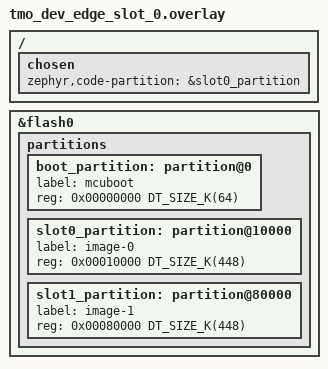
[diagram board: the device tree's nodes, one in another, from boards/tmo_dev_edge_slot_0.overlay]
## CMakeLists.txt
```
# Copyright (c) 2022 T-Mobile USA, Inc.
#
# SPDX-License-Identifier: Apache-2.0

cmake_minimum_required(VERSION 3.20.0)

find_package(Zephyr REQUIRED HINTS $ENV{ZEPHYR_BASE})
project(wake_sleep)

# TODO: Remove the following after the stderror.h workacound is addressed/removed.
#
# add_definitions(-include /Users/john/Work/zephyrproject-rebase/DevEdge-IoTDevKit-ZephyrSDK/samples/wake_sleep/src/stderror.h)
# target_precompile_headers(app
# #   PUBLIC
# #     project_header.h
#   PRIVATE
#     [["src/stderror.h"]]
#     <unordered_map>
# )

# TODO: ...additionally, uncomment the following and remove the subquent two lines
# target_sources(app PRIVATE "src/main.c")
FILE(GLOB app_sources src/*.c)
target_sources(app PRIVATE ${app_sources})
```

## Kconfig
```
# Copyright (c) 2022 T-Mobile USA, Inc.
#
# SPDX-License-Identifier: Apache-2.0

mainmenu "wake_sleep application settings"

config WAKE_TIMER_DURATION
    int "Wake timer timeout in seconds, 0 = diaabled"
    default 0

config WAKE_TIMER_PERIOD
    int "Wake timer period in seconds, 0 = disabled"
    default 0

source "Kconfig.zephyr"
```

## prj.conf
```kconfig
# Copyright (c) 2022 T-Mobile USA, Inc.
#
# SPDX-License-Identifier: Apache-2.0

# UART support
# CONFIG_SERIAL=y
# CONFIG_SHELL_BACKEND_SERIAL_RX_RING_BUFFER_SIZE=1024

# CONFIG_RING_BUFFER=y
# CONFIG_SOC_FLASH_GECKO=y

# CONFIG_ADC=y
# CONFIG_ADC_SHELL=n
# Enable support for the flash hardware.
# CONFIG_FLASH=y
# CONFIG_I2C=y

# CONFIG_SPI=y
# CONFIG_SPI_NOR=y
# CONFIG_SPI_GECKO=y

# Murata 1SC modem support
CONFIG_MODEM=y
# CONFIG_MODEM_SHELL=y
CONFIG_MODEM_MURATA_1SC=y
CONFIG_MODEM_MURATA_1SC_APN="CATM.T-MOBILE.COM"

# Generic networking options
CONFIG_NETWORKING=y
# CONFIG_NET_SHELL=n
CONFIG_NET_NATIVE=n
CONFIG_NET_OFFLOAD=y
CONFIG_NET_IPV6_DAD=n
CONFIG_NET_UDP=n
CONFIG_NET_TCP=n
CONFIG_NET_IPV6=n
CONFIG_NET_IPV4=y
CONFIG_DNS_RESOLVER=n
CONFIG_POSIX_MAX_FDS=15
CONFIG_HTTP_CLIENT=n

# Network management events
# CONFIG_NET_CONNECTION_MANAGER=y
# CONFIG_NET_MGMT=y
# CONFIG_NET_MGMT_EVENT=y

# Debugging
# CONFIG_DEBUG_OPTIMIZATIONS=y

# Logging
CONFIG_LOG=y
CONFIG_LOG_MODE_MINIMAL=y
# CONFIG_LOG_FUNC_NAME_PREFIX_ERR=y
# CONFIG_LOG_FUNC_NAME_PREFIX_WRN=y
# CONFIG_LOG_FUNC_NAME_PREFIX_INF=y
# CONFIG_LOG_FUNC_NAME_PREFIX_DBG=y
# CONFIG_LOG_BACKEND_SHOW_COLOR=y
# CONFIG_LOG_BACKEND_FORMAT_TIMESTAMP=y
# CONFIG_LOG_TIMESTAMP_64BIT=y
# CONFIG_NET_LOG=y

# Required to disable default behavior of deep sleep on timeout
# CONFIG_CONSOLE_SUBSYS=y
# CONFIG_CONSOLE_GETLINE=y

# Network buffers
# CONFIG_NET_PKT_RX_COUNT=1
# CONFIG_NET_PKT_TX_COUNT=1
# CONFIG_NET_BUF_RX_COUNT=1
# CONFIG_NET_BUF_TX_COUNT=1
# CONFIG_NET_CONTEXT_NET_PKT_POOL=y
# CONFIG_NET_BUF_DATA_SIZE=60

# RS9116
CONFIG_WIFI=y
CONFIG_WIFI_RS9116W=y
# CONFIG_GPIO=y

#CONFIG_TEST_RANDOM_GENERATOR=y

# CONFIG_INIT_STACKS=y

# CONFIG_MBEDTLS_DTLS=y

# CONFIG_NET_SOCKETS=y
# CONFIG_NET_SOCKETS_OFFLOAD=y
# CONFIG_NET_SOCKETS_POSIX_NAMES=y
# CONFIG_NET_SOCKETS_POLL_MAX=4
# CONFIG_NET_SOCKETS_SOCKOPT_TLS=y
# CONFIG_NET_SOCKETS_TLS_MAX_CONTEXTS=4
# CONFIG_NET_SOCKETS_ENABLE_DTLS=y


# Bluetooth / BLE
# CONFIG_BT=y
# CONFIG_BT_CUSTOM=y
# CONFIG_BT_RS9116W=y
# CONFIG_BT_PERIPHERAL=y
# CONFIG_BT_SMP=y
# CONFIG_BT_MAX_PAIRED=2
# CONFIG_BT_DEBUG=n

# Sensors
# CONFIG_SENSOR=y
# CONFIG_SENSOR_SHELL=y

# Stack sizes
# CONFIG_MAIN_STACK_SIZE=4096
# CONFIG_SHELL_STACK_SIZE=4096

# MBED TLS configuration
# CONFIG_MBEDTLS=y
# CONFIG_MBEDTLS_BUILTIN=y

# CONFIG_NEWLIB_LIBC=y
# CONFIG_MINIMAL_LIBC_MALLOC=y
# CONFIG_MINIMAL_LIBC_MALLOC_ARENA_SIZE=2048

# Set number IPv4 network interfaces
# CONFIG_NET_IF_MAX_IPV4_COUNT=2
# CONFIG_NET_IF_MAX_IPV6_COUNT=2

#CONFIG_FS_LOG_LEVEL_DBG=y

# CONFIG_HEAP_MEM_POOL_SIZE=16384

# CONFIG_SHELL=y
# CONFIG_SHELL_LOG_LEVEL_INF=y
# CONFIG_SHELL_CMD_BUFF_SIZE=2100

# CONFIG_FILE_SYSTEM=y
# CONFIG_FILE_SYSTEM_SHELL=y
# CONFIG_FILE_SYSTEM_LITTLEFS=y

# CONFIG_FLASH_MAP=y
# CONFIG_FLASH_PAGE_LAYOUT=y

# CONFIG_RS9116W_TLS_OFFLOAD=y

# CONFIG_TMO_SHELL_SSID=""
# CONFIG_TMO_SHELL_PSK=""

# CONFIG_RS9116_DNS_SERVER_IP_ADDRESSES=y
# CONFIG_RS9116_IPV4_DNS_SERVER1="8.8.8.8"
# CONFIG_RS9116_IPV6_DNS_SERVER1="2001:4860:4860::8888"

# CONFIG_MODEM_MURATA_1SC_SOCKET_COUNT=4
# CONFIG_WISECONNECT_SOCKETS_COUNT=6

# CONFIG_SHELL_GETOPT=y
# CONFIG_PING=y

# CONFIG_MODEM_SMS_IN_MSG_MAX_LEN=200
# CONFIG_MODEM_SMS_OUT_MSG_MAX_LEN=200

#Ekermit
# CONFIG_SEGGER_RTT_MODE_BLOCK_IF_FIFO_FULL=y
# CONFIG_LOG_BACKEND_RTT=n
# CONFIG_TMO_SHELL_BUILD_EK=y

#Power Managment
CONFIG_PM=y
CONFIG_PM_DEVICE=y

# CONFIG_BT_DEVICE_NAME_DYNAMIC=y
# CONFIG_LOG_PRINTK=n

# CONFIG_THREAD_NAME=y
# CONFIG_STATS=y
# CONFIG_PM_STATS=y
# CONFIG_IDLE_STACK_SIZE=640
# CONFIG_ZTEST_NEW_API=y

# The following is for the accelorometer
# CONFIG_STDOUT_CONSOLE=y
# CONFIG_I2C=y
# CONFIG_SENSOR=y
# CONFIG_LIS2DW12=y
# CONFIG_LIS2DW12_TRIGGER_GLOBAL_THREAD=y
# CONFIG_LIS2DW12_TAP=y
# CONFIG_LIS2DW12_THRESHOLD=y
# CONFIG_CBPRINTF_FP_SUPPORT=y
# CONFIG_ASSERT=y

# CONFIG_LED_PWM=y
# CONFIG_PWM=y
# # CONFIG_PWM_SHELL=y
# CONFIG_PWM_GECKO=y
CONFIG_GPIO=y

# Stack size
CONFIG_MAIN_STACK_SIZE=4096
# CONFIG_USERSPACE=n

# CONFIG_WAKE_TIMER_DURATION=0
```

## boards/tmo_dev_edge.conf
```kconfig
# Copyright (c) 2022 T-Mobile USA, Inc.
#
# SPDX-License-Identifier: Apache-2.0

# CONFIG_BT_DEVICE_NAME="TMO DevEdge"
CONFIG_POSIX_CLOCK=y
CONFIG_CMU_HFCLK_HFXO=y
# CONFIG_DEVICE_SHELL=y
# CONFIG_GPIO_SHELL=y
CONFIG_SOC_GECKO_EMU_DCDC=y
CONFIG_SOC_GECKO_EMU_DCDC_MODE_OFF=y
CONFIG_I2C=y
CONFIG_SPI=y
CONFIG_REBOOT=y
CONFIG_COUNTER=y
CONFIG_LED=y
CONFIG_LED_PWM=y
# CONFIG_LED_SHELL=y
CONFIG_PWM=y
# CONFIG_PWM_SHELL=y
CONFIG_PWM_GECKO=y
CONFIG_SENSOR=y
# CONFIG_SENSOR_SHELL=y
CONFIG_LPS22HH=y
CONFIG_LIS2DW12=y
CONFIG_TSL2540=y
CONFIG_TMP108=y
CONFIG_CXD5605=y
```

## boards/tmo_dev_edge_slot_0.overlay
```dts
/*
 * Copyright (c) 2021 T-Mobile USA, Inc.
 *
 * SPDX-License-Identifier: Apache-2.0
 */

/{
chosen {
                zephyr,code-partition = &slot0_partition;
        };
};

&flash0 {

    partitions {
	boot_partition: partition@0 {
	    label = "mcuboot";
	    reg = <0x00000000 DT_SIZE_K(64)>;
	};
	slot0_partition: partition@10000 {
	    label = "image-0";
	    reg = <0x00010000 DT_SIZE_K(448)>;
	};
	slot1_partition: partition@80000 {
	    label = "image-1";
	    reg = <0x00080000 DT_SIZE_K(448)>;
	};
    };
};
```

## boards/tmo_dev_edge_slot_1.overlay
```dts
/*
 * Copyright (c) 2021 T-Mobile USA, Inc.
 *
 * SPDX-License-Identifier: Apache-2.0
 */

/{
chosen {
                zephyr,code-partition = &slot1_partition;
        };
};

&flash0 {

    partitions {
	boot_partition: partition@0 {
	    label = "mcuboot";
	    reg = <0x00000000 DT_SIZE_K(64)>;
	};
	slot0_partition: partition@10000 {
	    label = "image-0";
	    reg = <0x00010000 DT_SIZE_K(448)>;
	};
	slot1_partition: partition@80000 {
	    label = "image-1";
	    reg = <0x00080000 DT_SIZE_K(448)>;
	};
    };
};
```

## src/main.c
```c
/*
 * Copyright (c) 2022 T-Mobile USA, Inc.
 *
 * SPDX-License-Identifier: Apache-2.0
 */

#include <zephyr/drivers/gpio.h>
#include <zephyr/drivers/led.h>
#include <zephyr/pm/device.h>
#include <zephyr/pm/device_runtime.h>
#include <zephyr/pm/pm.h>
#include <zephyr/pm/policy.h>
#include <zephyr/pm/state.h>

#include <zephyr/logging/log.h>
LOG_MODULE_DECLARE(wake_sleep, CONFIG_PM_LOG_LEVEL);

#include <stdio.h>
#include <string.h>

/*
 * TODO: Remove the following workaround, and replace its functionality with a permanent, standard
 * solution.
 */
#include "strerror.h"

/*
 * Thread defines
 */
#define THREAD_PRIORITY K_PRIO_COOP(5)

/*
 * Deep-sleep defines
 */
#define SLEEP_DURATION K_MSEC(1)
#define SLEEP_MODE     PM_STATE_RUNTIME_IDLE

/*
 * Pushbutton defines and data
 */
#define SW0_NODE DT_ALIAS(sw0)
#if !DT_NODE_HAS_STATUS(SW0_NODE, okay)
#error "Unsupported board: sw0 device-tree alias is not defined"
#endif
static const struct gpio_dt_spec button = GPIO_DT_SPEC_GET_OR(SW0_NODE, gpios, {0});
static struct gpio_callback button_cb_data;

/*
 * LED data
 */
const struct device *pwm_leds;

/*
 * Thread data
 */
static struct k_thread thread_id;

/*
 * Timer interrupt service routine
 */
#if defined(CONFIG_WAKE_TIMER_DURATION) && defined(CONFIG_WAKE_TIMER_PERIOD)
#if (0 != CONFIG_WAKE_TIMER_DURATION) && (0 != CONFIG_WAKE_TIMER_PERIOD)
static void timer_isr(struct k_timer *dummy)
{
	k_thread_resume(&thread_id);
}
#define TIMER_STOP_FN NULL
static K_TIMER_DEFINE(pm_timer, timer_isr, TIMER_STOP_FN);
#endif
#endif

/*
 * User Push Button (sw0) interrupt service routine
 */
static void user_push_button_intr_callback(const struct device *port, struct gpio_callback *cb,
					   gpio_port_pins_t pin_mask)
{
	k_thread_resume(&thread_id);
}

/*
 * Gate the various LEDs on and off
 */
static void gate_leds(enum pm_device_action pm_device_action)
{

	switch (pm_device_action) {
	case PM_DEVICE_ACTION_SUSPEND:
		puts("Turn on white LED");
		led_set_brightness(pwm_leds, 0, 100);
		led_on(pwm_leds, 0); /* White */
		break;

	case PM_DEVICE_ACTION_RESUME:
		puts("Turn on red LED");
		led_set_brightness(pwm_leds, 1, 100);
		led_on(pwm_leds, 1); /* Red */
		break;

	case PM_DEVICE_ACTION_TURN_ON:
		puts("Turn on green LED");
		led_set_brightness(pwm_leds, 2, 100);
		led_on(pwm_leds, 2); /* Green */
		break;

	case PM_DEVICE_ACTION_TURN_OFF:
		puts("Turn on blue LED");
		led_set_brightness(pwm_leds, 3, 100);
		led_on(pwm_leds, 3); /* Blue */
		break;

	default:
		// puts("Turn off LEDs");
		led_off(pwm_leds, 0);
		led_off(pwm_leds, 1);
		led_off(pwm_leds, 2);
		led_off(pwm_leds, 3);
		led_set_brightness(pwm_leds, 0, 0);
		led_set_brightness(pwm_leds, 1, 0);
		led_set_brightness(pwm_leds, 2, 0);
		led_set_brightness(pwm_leds, 3, 0);
		break;
	}
}

/*
 * The power management thread
 */
static K_THREAD_STACK_DEFINE(thread_stack, 1024);
static void pm_thread(void *this_thread, void *p2, void *p3)
{
	ARG_UNUSED(p2);
	ARG_UNUSED(p3);

#define STRUCT_INIT(enumerator)                                                                    \
	{                                                                                          \
		enumerator, #enumerator                                                            \
	}
	const struct {
		enum pm_device_action value;
		const char *name;
	} device_action[] = {
		STRUCT_INIT(PM_DEVICE_ACTION_SUSPEND), STRUCT_INIT(PM_DEVICE_ACTION_TURN_OFF),
		STRUCT_INIT(PM_DEVICE_ACTION_TURN_ON), STRUCT_INIT(PM_DEVICE_ACTION_RESUME)};
#undef STRUCT_INIT
	const size_t device_action_size = sizeof device_action / sizeof *device_action;

	const struct device *devices;
	const size_t n_devices = z_device_get_all_static(&devices);

	for (unsigned char action_index = 0; true;
	     action_index = (action_index + 1) % device_action_size) {

		gate_leds(-2);
		k_thread_suspend((struct k_thread *)this_thread);
		printf("%s(): awake\n", __func__);
		gate_leds(device_action[action_index].value);

		printf("device_action[%d].value: %d, device_action[%d].name: %s\n", action_index,
		       device_action[action_index].value, action_index,
		       device_action[action_index].name);
		for (size_t ii = 0; ii < n_devices; ii++) {
			int ret;
			enum pm_device_state pm_device_state;

			/*
			 * Ignore busy devices, wake up source and devices with
			 * runtime PM enabled.
			 */
			if (devices[ii].pm == NULL || pm_device_is_busy(&devices[ii]) ||
			    pm_device_runtime_is_enabled(&devices[ii])) {
				continue;
			}

			ret = pm_device_action_run(&devices[ii], device_action[action_index].value);
			(void)pm_device_state_get(&devices[ii], &pm_device_state);

			if (ret) {
				LOG_WRN("%s(): %s call status: %d (%s), device state: %s", __func__,
					devices[ii].name, ret, strerror(ret),
					pm_device_state_str(pm_device_state));
			} else {
				LOG_INF("%s(): %s call status: %d (%s), device state: %s", __func__,
					devices[ii].name, ret, strerror(ret),
					pm_device_state_str(pm_device_state));
			}
		}

		gate_leds(-1);
		printf("%s(): asleep\n\n", __func__);
	}
}

/* Prevent the deep sleep (non-recoverable shipping mode) from being entered on
 * long timeouts or `K_FOREVER` due to the default residency policy.
 *
 * This has to be done before anything tries to sleep, which means
 * before the threading system starts up between PRE_KERNEL_2 and
 * POST_KERNEL.  Do it at the start of PRE_KERNEL_2.
 */
static int disable_deep_sleep(const struct device *dev)
{
	ARG_UNUSED(dev);

	pm_policy_state_lock_get(PM_STATE_SOFT_OFF, PM_ALL_SUBSTATES);
	return 0;
}
SYS_INIT(disable_deep_sleep, PRE_KERNEL_2, 0);

/*
 * Print usage information
 */
static void greeting()
{
	puts("\n\n\t\t\tWelcome to T-Mobile DevEdge!\n\n"
	     "This application aims to demonstrate the Gecko's Energy Mode 2 (EM2) (Deep\n"
	     "Sleep Mode) and Wake capabilities in conjunction with the SW0 interrupt pin,\n"
	     "which is connected to the user pushbutton switch of the DevEdge module.\n\n"
	     "Press and release the user pushbutton to advance from one power management\n"
	     "mode to the next.\n");
}

/*
 *	Set up the GPIO and interrupt service structures
 */
static void setup(void)
{
	int ret;

	LOG_INF("Setting up GPIO and ISR structures");

	pwm_leds = device_get_binding("pwmleds");

	if (!device_is_ready(button.port)) {
		LOG_ERR("Error: button device %s is not ready", button.port->name);
		return;
	}

	ret = gpio_pin_configure_dt(&button, GPIO_INPUT | GPIO_PULL_UP);
	if (ret != 0) {
		LOG_ERR("Error %d: failed to configure %s pin %d", ret, button.port->name,
			button.pin);
		return;
	}

	ret = gpio_pin_interrupt_configure_dt(&button, GPIO_INT_EDGE_RISING);
	if (ret != 0) {
		LOG_ERR("Error %d: failed to configure interrupt on %s pin %d", ret,
			button.port->name, button.pin);
		return;
	}
	gpio_init_callback(&button_cb_data, user_push_button_intr_callback, BIT(button.pin));
	gpio_add_callback(button.port, &button_cb_data);
	LOG_INF("Set up button at %s pin %d\n", button.port->name, button.pin);
}

/*
 * Entry point
 */
void main(void)
{
	/* Set up hardware and interrupt service routines */
	setup();

	/* Print usage information */
	greeting();

	/* Create the power management thread, and schedule it for execution. */
	k_thread_create(
		/* Thread ID and stack specifics */
		&thread_id, thread_stack, K_THREAD_STACK_SIZEOF(thread_stack),
		/* Thread entry point function and (3) option parameters */
		pm_thread, &thread_id, NULL, NULL,
		/* Thread priority, options, and scheduling delay */
		THREAD_PRIORITY, K_INHERIT_PERMS, K_NO_WAIT);

#if defined(CONFIG_WAKE_TIMER_DURATION) && defined(CONFIG_WAKE_TIMER_PERIOD)
#if (0 == CONFIG_WAKE_TIMER_DURATION) || (0 == CONFIG_WAKE_TIMER_PERIOD)
#warning Timer disabled
#else
#if (15 > CONFIG_WAKE_TIMER_DURATION)
#error Timer duration must be 15 seconds or more
#elif (20 > CONFIG_WAKE_TIMER_PERIOD)
#error Timer period must be 20 seconds or more
#else
	/* Start the power management periodic timer. */
	k_timer_start(&pm_timer, K_SECONDS(CONFIG_WAKE_TIMER_DURATION),
		      K_SECONDS(CONFIG_WAKE_TIMER_PERIOD));
#endif
#endif
#endif

#ifdef SLEEP_DURATION
	pm_state_force(0u, &(struct pm_state_info){SLEEP_MODE, 0, 0});
	k_sleep(SLEEP_DURATION);
#endif
}
```

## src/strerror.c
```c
/*
 * Copyright (c) 2022 T-Mobile USA, Inc.
 *
 * SPDX-License-Identifier: Apache-2.0
 */

/*
 * TODO: Replace this interim implementation with the system default, assuming it exists.
 */

#include "strerror.h"
#include <stdlib.h>
/*
 * Interim support for strerror
 */
#ifdef sys_nerr
const char *strerror(int error_value)
{
	error_value = abs(error_value);
	if (sys_nerr < error_value) {
		return "";
	} else {
		return sys_errlist[error_value];
	}
}
#endif
```

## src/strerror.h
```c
/*
 * Copyright (c) 2022 T-Mobile USA, Inc.
 *
 * SPDX-License-Identifier: Apache-2.0
 */

/*
 * TODO: Replace this interim implementation with the system default, assuming it exists.
 */

#ifndef STRERROR_WORKAROUND_H_
#define STRERROR_WORKAROUND_H_

#ifdef __cplusplus
extern "C" {
#endif
/*
 * The following is included for Zephyr's non-standard support of strerror
 */
#ifndef sys_nerr
#include "strerror_table.h"
#define strerror strerror_extended
const char *strerror(int error_value);
#endif

#ifdef __cplusplus
}
#endif /* __cplusplus */

#endif /* STRERROR_WORKAROUND_H_ */
```

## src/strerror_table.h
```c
/*
 * Copyright (c) 2022 T-Mobile USA, Inc.
 *
 * SPDX-License-Identifier: Apache-2.0
 */

/*
 * TODO: Determine the method or configuration to remove this header file and
 * reference the generated version, which resides in the following relative path:
 * .../wake_sleep/zephyr/include/generated/libc/minimal/strerror_table.h.
 */

#include <errno.h>
#include <stdint.h>
#include <string.h>

#include <zephyr/sys/util.h>

#define sys_nerr 141
static const char *const sys_errlist[sys_nerr] = {
[0] = "Success",
[EPERM] = "Not owner",
[ENOENT] = "No such file or directory",
[ESRCH] = "No such context",
[EINTR] = "Interrupted system call",
[EIO] = "I/O error",
[ENXIO] = "No such device or address",
[ENOEXEC] = "Exec format error",
[EBADF] = "Bad file number",
[ECHILD] = "No children",
[EAGAIN] = "No more contexts",
[ENOMEM] = "Not enough core",
[EACCES] = "Permission denied",
[EFAULT] = "Bad address",
[ENOTBLK] = "Block device required",
[EBUSY] = "Mount device busy",
[EEXIST] = "File exists",
[EXDEV] = "Cross-device link",
[ENODEV] = "No such device",
[ENOTDIR] = "Not a directory",
[EISDIR] = "Is a directory",
[EINVAL] = "Invalid argument",
[ENFILE] = "File table overflow",
[EMFILE] = "Too many open files",
[ENOTTY] = "Not a typewriter",
[ETXTBSY] = "Text file busy",
[EFBIG] = "File too large",
[ENOSPC] = "No space left on device",
[ESPIPE] = "Illegal seek",
[EROFS] = "Read-only file system",
[EMLINK] = "Too many links",
[EPIPE] = "Broken pipe",
[EDOM] = "Argument too large",
[ERANGE] = "Result too large",
[ENOMSG] = "Unexpected message type",
[EDEADLK] = "Resource deadlock avoided",
[ENOLCK] = "No locks available",
[ENOSTR] = "STREAMS device required",
[ENODATA] = "Missing expected message data",
[ETIME] = "STREAMS timeout occurred",
[ENOSR] = "Insufficient memory",
[EPROTO] = "Generic STREAMS error",
[EBADMSG] = "Invalid STREAMS message",
[ENOSYS] = "Function not implemented",
[ENOTEMPTY] = "Directory not empty",
[ENAMETOOLONG] = "File name too long",
[ELOOP] = "Too many levels of symbolic links",
[EOPNOTSUPP] = "Operation not supported on socket",
[EPFNOSUPPORT] = "Protocol family not supported",
[ECONNRESET] = "Connection reset by peer",
[ENOBUFS] = "No buffer space available",
[EAFNOSUPPORT] = "Addr family not supported",
[EPROTOTYPE] = "Protocol wrong type for socket",
[ENOTSOCK] = "Socket operation on non-socket",
[ENOPROTOOPT] = "Protocol not available",
[ESHUTDOWN] = "Can't send after socket shutdown",
[ECONNREFUSED] = "Connection refused",
[EADDRINUSE] = "Address already in use",
[ECONNABORTED] = "Software caused connection abort",
[ENETUNREACH] = "Network is unreachable",
[ENETDOWN] = "Network is down",
[ETIMEDOUT] = "Connection timed out",
[EHOSTDOWN] = "Host is down",
[EHOSTUNREACH] = "No route to host",
[EINPROGRESS] = "Operation now in progress",
[EALREADY] = "Operation already in progress",
[EDESTADDRREQ] = "Destination address required",
[EMSGSIZE] = "Message size",
[EPROTONOSUPPORT] = "Protocol not supported",
[ESOCKTNOSUPPORT] = "Socket type not supported",
[EADDRNOTAVAIL] = "Can't assign requested address",
[ENETRESET] = "Network dropped connection on reset",
[EISCONN] = "Socket is already connected",
[ENOTCONN] = "Socket is not connected",
[ETOOMANYREFS] = "Too many references: can't splice",
[ENOTSUP] = "Unsupported value",
[EILSEQ] = "Illegal byte sequence",
[EOVERFLOW] = "Value overflow",
[ECANCELED] = "Operation canceled",
};
static const uint8_t sys_errlen[sys_nerr] = {
[0] = 8,
[EPERM] = 10,
[ENOENT] = 26,
[ESRCH] = 16,
[EINTR] = 24,
[EIO] = 10,
[ENXIO] = 26,
[ENOEXEC] = 18,
[EBADF] = 16,
[ECHILD] = 12,
[EAGAIN] = 17,
[ENOMEM] = 16,
[EACCES] = 18,
[EFAULT] = 12,
[ENOTBLK] = 22,
[EBUSY] = 18,
[EEXIST] = 12,
[EXDEV] = 18,
[ENODEV] = 15,
[ENOTDIR] = 16,
[EISDIR] = 15,
[EINVAL] = 17,
[ENFILE] = 20,
[EMFILE] = 20,
[ENOTTY] = 17,
[ETXTBSY] = 15,
[EFBIG] = 15,
[ENOSPC] = 24,
[ESPIPE] = 13,
[EROFS] = 22,
[EMLINK] = 15,
[EPIPE] = 12,
[EDOM] = 19,
[ERANGE] = 17,
[ENOMSG] = 24,
[EDEADLK] = 26,
[ENOLCK] = 19,
[ENOSTR] = 24,
[ENODATA] = 30,
[ETIME] = 25,
[ENOSR] = 20,
[EPROTO] = 22,
[EBADMSG] = 24,
[ENOSYS] = 25,
[ENOTEMPTY] = 20,
[ENAMETOOLONG] = 19,
[ELOOP] = 34,
[EOPNOTSUPP] = 34,
[EPFNOSUPPORT] = 30,
[ECONNRESET] = 25,
[ENOBUFS] = 26,
[EAFNOSUPPORT] = 26,
[EPROTOTYPE] = 31,
[ENOTSOCK] = 31,
[ENOPROTOOPT] = 23,
[ESHUTDOWN] = 33,
[ECONNREFUSED] = 19,
[EADDRINUSE] = 23,
[ECONNABORTED] = 33,
[ENETUNREACH] = 23,
[ENETDOWN] = 16,
[ETIMEDOUT] = 21,
[EHOSTDOWN] = 13,
[EHOSTUNREACH] = 17,
[EINPROGRESS] = 26,
[EALREADY] = 30,
[EDESTADDRREQ] = 29,
[EMSGSIZE] = 13,
[EPROTONOSUPPORT] = 23,
[ESOCKTNOSUPPORT] = 26,
[EADDRNOTAVAIL] = 31,
[ENETRESET] = 36,
[EISCONN] = 28,
[ENOTCONN] = 24,
[ETOOMANYREFS] = 34,
[ENOTSUP] = 18,
[EILSEQ] = 22,
[EOVERFLOW] = 15,
[ECANCELED] = 19,
};
```
